# CPSW_PORT register map
Vendor: Texas Instruments
Peripheral module from a debugger description file (folder am437x).
Registers are 32-bit, access per field, no defined reset value unless marked. A register's access mark holds for its fields unless they carry their own. Offsets are as the file gives them; lines under a group give offsets from that group; [hi:lo] are bit positions; {n}, {i} and the like mark numbered series; 'fields as' and 'values as' point back to an identical list; <NAME> marks a mode.

## CPSW_PORT
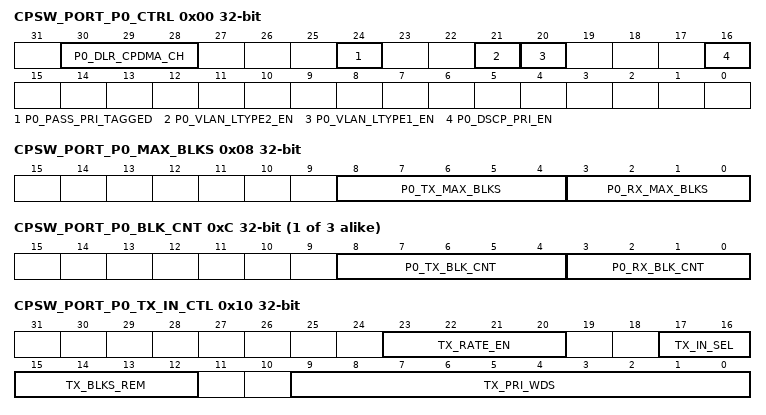
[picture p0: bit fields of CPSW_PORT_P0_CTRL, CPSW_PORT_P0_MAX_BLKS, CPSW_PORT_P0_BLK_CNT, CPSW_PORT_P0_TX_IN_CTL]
0x00 CPSW_PORT_P0_CTRL — CPSW PORT 0 CONTROL REGISTER
  [30:28] P0_DLR_CPDMA_CH rw — Port 0 DLR CPDMA Channel This field indicates the CPDMA channel that DLR packets will be received on.
  [24] P0_PASS_PRI_TAGGED rw — Port 0 Pass Priority Tagged
    1=en_2_0x1 (Priority tagged packets are processed unchanged.); 0=en_1_0x0 (Priority tagged packets have the zero VID replaced with the input port P0_PORT_VLAN[11 to 0])
  [21] P0_VLAN_LTYPE2_EN rw — Port 0 VLAN LTYPE 2 enable
    1=en_2_0x1 (Enabled); 0=en_1_0x0 (Disabled)
  [20] P0_VLAN_LTYPE1_EN rw — Port 0 VLAN LTYPE 1 enable
    1=en_2_0x1 (Enabled); 0=en_1_0x0 (Disabled)
  [16] P0_DSCP_PRI_EN rw — Port 0 DSCP Priority Enable. [[br]]All non-tagged IPV4 packets have their received packet priority determined by mapping the 6 TOS bits through the port DSCP priority mapping registers. [[br]]
    1=en_2_0x1 (DSCP priority enabled); 0=en_1_0x0 (DSCP priority disabled)
0x08 CPSW_PORT_P0_MAX_BLKS — CPSW PORT 0 MAXIMUM FIFO BLOCKS REGISTER
  [8:4] P0_TX_MAX_BLKS rw — Transmit FIFO Maximum Blocks - This value is the maximum number of 1k memory blocks that may be allocated to the FIFO's logical transmit priority queues. [[br]]0x10 is the recommended value of p0_tx_max_blks. [[br]]Port 0 should remain in flow control mode. [[br]]0xe is the minimum value tx max blks. [[br]]
  [3:0] P0_RX_MAX_BLKS rw — Receive FIFO Maximum Blocks - This value is the maximum number of 1k memory blocks that may be allocated to the FIFO's logical receive queue. [[br]]0x4 is the recommended value. [[br]]0x3 is the minimum value rx max blks and 0x6 is the maximum value. [[br]]
{0xC+0x100*i} CPSW_PORT_P{i}_BLK_CNT ro (i=0..2) — CPSW PORT {i} FIFO BLOCK USAGE COUNT (READ ONLY)
  [8:4] P{i}_TX_BLK_CNT — Port {i} Transmit Block Count Usage - This value is the number of blocks allocated to the FIFO logical transmit queues. [[br]]
  [3:0] P{i}_RX_BLK_CNT — Port {i} Receive Block Count Usage - This value is the number of blocks allocated to the FIFO logical receive queues. [[br]]
0x10 CPSW_PORT_P0_TX_IN_CTL — CPSW PORT 0 TRANSMIT FIFO CONTROL
  [23:20] TX_RATE_EN rw — Transmit FIFO Input Rate Enable
  [17:16] TX_IN_SEL rw — Transmit FIFO Input Queue Type Select. [[br]]Note that Dual MAC mode is not compatible with escalation or shaping because dual mac mode forces round robin priority on FIFO egress. [[br]]
    3=en_4_0x3 (Reserved); 2=en_3_0x2 (Rate Limit mode); 1=en_2_0x1 (Dual MAC mode); 0=en_1_0x0 (Normal priority mode)
  [15:12] TX_BLKS_REM rw — Transmit FIFO Input Blocks to subtract in dual mac mode
  [9:0] TX_PRI_WDS rw — Transmit FIFO Words in queue
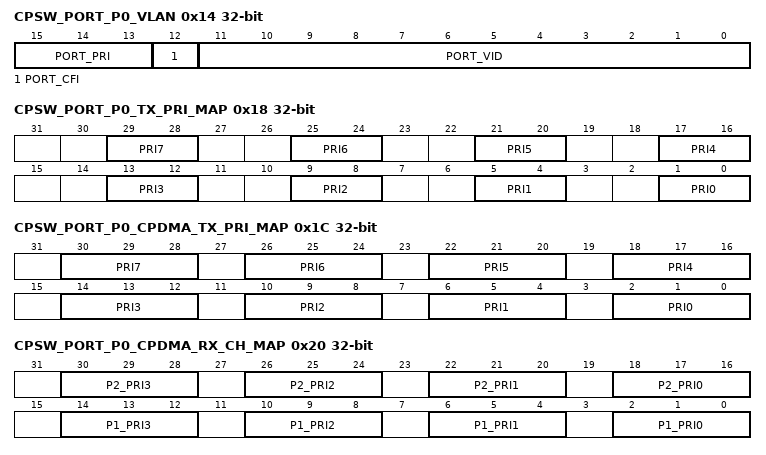
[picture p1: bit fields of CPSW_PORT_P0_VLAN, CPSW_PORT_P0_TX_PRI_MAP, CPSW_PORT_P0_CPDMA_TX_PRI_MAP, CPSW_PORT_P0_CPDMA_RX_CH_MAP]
0x14 CPSW_PORT_P0_VLAN — CPSW PORT 0 VLAN REGISTER
  [15:13] PORT_PRI rw — Port VLAN Priority (7 is highest priority)
  [12] PORT_CFI rw — Port CFI bit
  [11:0] PORT_VID rw — Port VLAN ID
0x18 CPSW_PORT_P0_TX_PRI_MAP — CPSW PORT 0 TX HEADER PRI TO SWITCH PRI MAPPING REGISTER
  [4n+1:4n] PRI{n} rw (n=0..7) — Priority [[br]]{n} - A packet header priority of {0x0+n} is given this switch queue pri.
0x1C CPSW_PORT_P0_CPDMA_TX_PRI_MAP — CPSW CPDMA TX (PORT 0 RX) PKT PRIORITY TO HEADER PRIORITY
  [4n+2:4n] PRI{n} rw (n=0..7) — Priority [[br]]{n} - A packet pri of {0x0+n} is mapped (changed) to this header packet pri.
0x20 CPSW_PORT_P0_CPDMA_RX_CH_MAP — CPSW CPDMA RX (PORT 0 TX) SWITCH PRIORITY TO DMA CHANNEL
  [4n+18:4n+16] P2_PRI{n} rw (n=0..3) — Port 2 Priority {n} packets go to this CPDMA Rx Channel
  [4n+2:4n] P1_PRI{n} rw (n=0..3) — Port 1 Priority {n} packets go to this CPDMA Rx Channel
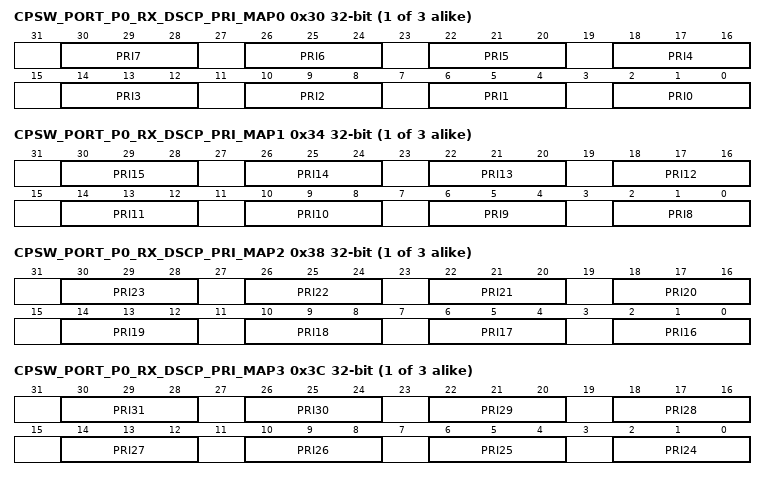
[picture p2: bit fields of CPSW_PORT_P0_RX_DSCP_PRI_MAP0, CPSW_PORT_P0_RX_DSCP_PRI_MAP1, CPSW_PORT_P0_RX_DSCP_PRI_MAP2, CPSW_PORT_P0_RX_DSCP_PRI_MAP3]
{0x30+0x100*i} CPSW_PORT_P{i}_RX_DSCP_PRI_MAP0 (i=0..2) — CPSW PORT {i} RX DSCP PRIORITY TO RX PACKET MAPPING REG 0
  [4n+2:4n] PRI{n} rw (n=0..7) — Priority {n}. [[br]]A packet TOS of 0d{n} is mapped to this received packet priority.
{0x34+0x100*i} CPSW_PORT_P{i}_RX_DSCP_PRI_MAP1 (i=0..2) — CPSW PORT {i} RX DSCP PRIORITY TO RX PACKET MAPPING REG 1
  [4n-30:4n-32] PRI{n} rw (n=8..15) — Priority {n}. [[br]]A packet TOS of 0d{n} is mapped to this received packet priority.
{0x38+0x100*i} CPSW_PORT_P{i}_RX_DSCP_PRI_MAP2 (i=0..2) — CPSW PORT {i} RX DSCP PRIORITY TO RX PACKET MAPPING REG 2
  [4n-62:4n-64] PRI{n} rw (n=16..23) — Priority {n}. [[br]]A packet TOS of 0d{n} is mapped to this received packet priority.
{0x3C+0x100*i} CPSW_PORT_P{i}_RX_DSCP_PRI_MAP3 (i=0..2) — CPSW PORT {i} RX DSCP PRIORITY TO RX PACKET MAPPING REG 3
  [30:28] PRI31 rw — Priority 31. [[br]]A packet TOS of 0d31 is mapped to this received packet priority.
  [26:24] PRI30 rw — Priority 30. [[br]]A packet TOS of 0d30 is mapped to this received packet priority.
  [22:20] PRI29 rw — Priority 29. [[br]]A packet TOS of 0d39 is mapped to this received packet priority.
  [4n-94:4n-96] PRI{n} rw (n=24..28) — Priority {n}. [[br]]A packet TOS of 0d{n} is mapped to this received packet priority.
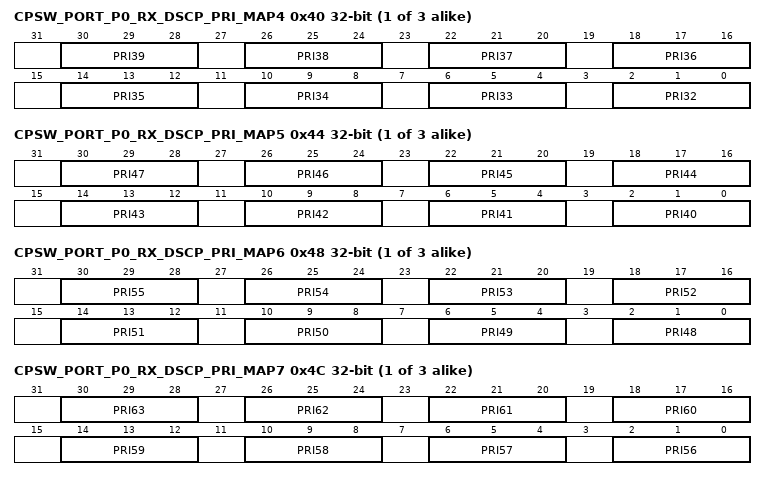
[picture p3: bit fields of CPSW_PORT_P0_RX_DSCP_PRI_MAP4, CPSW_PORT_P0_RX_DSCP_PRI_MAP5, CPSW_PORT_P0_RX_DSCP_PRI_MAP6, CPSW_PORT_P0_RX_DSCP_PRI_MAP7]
{0x40+0x100*i} CPSW_PORT_P{i}_RX_DSCP_PRI_MAP4 (i=0..2) — CPSW PORT {i} RX DSCP PRIORITY TO RX PACKET MAPPING REG 4
  [4n-126:4n-128] PRI{n} rw (n=32..39) — Priority {n}. [[br]]A packet TOS of 0d{n} is mapped to this received packet priority.
{0x44+0x100*i} CPSW_PORT_P{i}_RX_DSCP_PRI_MAP5 (i=0..2) — CPSW PORT {i} RX DSCP PRIORITY TO RX PACKET MAPPING REG 5
  [4n-158:4n-160] PRI{n} rw (n=40..47) — Priority {n}. [[br]]A packet TOS of 0d{n} is mapped to this received packet priority.
{0x48+0x100*i} CPSW_PORT_P{i}_RX_DSCP_PRI_MAP6 (i=0..2) — CPSW PORT {i} RX DSCP PRIORITY TO RX PACKET MAPPING REG 6
  [4n-190:4n-192] PRI{n} rw (n=48..55) — Priority {n}. [[br]]A packet TOS of 0d{n} is mapped to this received packet priority.
{0x4C+0x100*i} CPSW_PORT_P{i}_RX_DSCP_PRI_MAP7 (i=0..2) — CPSW PORT {i} RX DSCP PRIORITY TO RX PACKET MAPPING REG 7
  [4n-222:4n-224] PRI{n} rw (n=56..63) — Priority {n}. [[br]]A packet TOS of 0d{n} is mapped to this received packet priority.
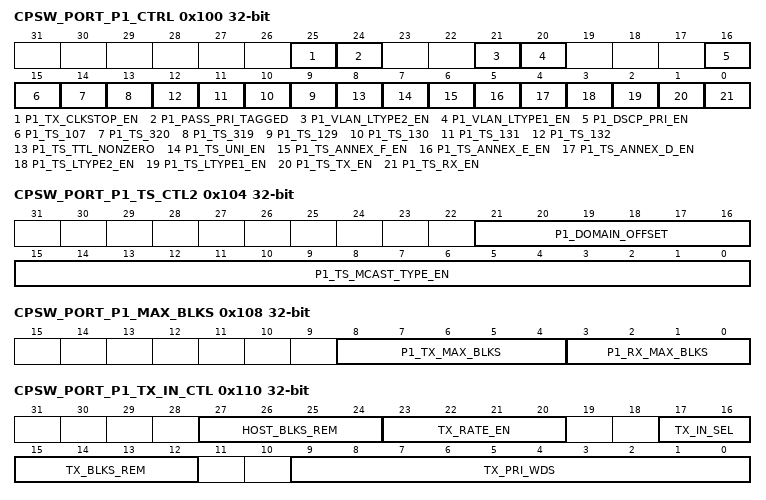
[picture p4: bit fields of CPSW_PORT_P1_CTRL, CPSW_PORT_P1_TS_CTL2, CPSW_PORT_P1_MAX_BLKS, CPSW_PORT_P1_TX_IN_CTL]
0x100 CPSW_PORT_P1_CTRL — CPSW PORT 1 CONTROL REGISTER
  [25] P1_TX_CLKSTOP_EN rw — Port 1 Transmit clockstop enable
    1=en_2_0x1 (RGMII transmit clockstop enabled. The transmit clock will be stopped after the LPI state is entered (and indicated to the CPRGMII) and the P1_Idle2LPI time is counted (counter value reused). The P1_Idle2LPI counter value must be greater than 9 transmit clocks (slowest clock).); 0=en_1_0x0 (RGMII transmit clockstop not enabled)
  [24] P1_PASS_PRI_TAGGED rw — Port 1 Pass Priority Tagged
    1=en_2_0x1 (Priority tagged packets are processed unchanged.); 0=en_1_0x0 (Priority tagged packets have the zero VID replaced with the input port P1_PORT_VLAN[11 to 0])
  [21] P1_VLAN_LTYPE2_EN rw — Port 1 VLAN LTYPE 2 enable
    1=en_2_0x1 (VLAN LTYPE2 enabled on transmit and receive); 0=en_1_0x0 (Disabled)
  [20] P1_VLAN_LTYPE1_EN rw — Port 1 VLAN LTYPE 1 enable
    1=en_2_0x1 (VLAN LTYPE1 enabled on transmit and receive); 0=en_1_0x0 (Disabled)
  [16] P1_DSCP_PRI_EN rw — Port 1 DSCP Priority Enable. [[br]]All non-tagged IPV4 packets have their received packet priority determined by mapping the 6 TOS bits through the port DSCP priority mapping registers.
    values as CPSW_PORT_P0_CTRL.P0_DSCP_PRI_EN
  [15] P1_TS_107 rw — Port 1 Time Sync Destination IP Address 107 enable
    1=en_2_0x1 (Destination IP address (dec) 224.0.0.107 is enabled.); 0=en_1_0x0 (Disabled)
  [14] P1_TS_320 rw — Port 1 Time Sync Destination Port Number 320 enable
    1=en_2_0x1 (Annex D (UDP/IPv4) time sync packet destination port number 320 (decimal) is enabled.); 0=en_1_0x0 (Disabled)
  [13] P1_TS_319 rw — Port 1 Time Sync Destination Port Number 319 enable
    1=en_2_0x1 (Annex D (UDP/IPv4) time sync packet destination port number 319 (decimal) is enabled.); 0=en_1_0x0 (DSCP priority disabled)
  [n-120] P1_TS_{n} rw (n=129..132) — Port 1 Time Sync Destination IP Address {n} enable
    1=en_2_0x1 (Annex D (UDP/IPv4) time sync packet destination IP address number {n} (decimal) is enabled.); 0=en_1_0x0 (DSCP priority disabled)
  [8] P1_TS_TTL_NONZERO rw — Port 1 Time Sync Time To Live Non-zero enable.
    1=en_2_0x1 (TTL may be any value); 0=en_1_0x0 (TTL must be zero)
  [7] P1_TS_UNI_EN rw — Port 1 Time Sync Unicast Enable
    1=en_2_0x1 (Unicast enabled); 0=en_1_0x0 (Unicast disabled)
  [6] P1_TS_ANNEX_F_EN rw — Port 1 Time Sync Annex F enable
    1=en_2_0x1 (Annex F enabled); 0=en_1_0x0 (Annex F disabled)
  [5] P1_TS_ANNEX_E_EN rw — Port 1 Time Sync Annex E enable
    1=en_2_0x1 (Annex E enabled); 0=en_1_0x0 (Annex E disabled)
  [4] P1_TS_ANNEX_D_EN rw — Port 1 Time Sync Annex D enable
    1=en_2_0x1 (Annex D enabled); 0=en_1_0x0 (Annex D disabled)
  [3] P1_TS_LTYPE2_EN rw — Port 1 Time Sync LTYPE 2 enable
    1=en_2_0x1 (Enabled); 0=en_1_0x0 (Disabled)
  [2] P1_TS_LTYPE1_EN rw — Port 1 Time Sync LTYPE 1 enable
    1=en_2_0x1 (Enabled); 0=en_1_0x0 (Disabled)
  [1] P1_TS_TX_EN rw — Port 1 Time Sync Transmit Enable
    1=en_2_0x1 (Enabled); 0=en_1_0x0 (Disabled)
  [0] P1_TS_RX_EN rw — Port 1 Time Sync Receive Enable
    1=en_2_0x1 (Port 1 Receive Time Sync enabled); 0=en_1_0x0 (Port 1 Receive Time Sync disabled)
0x104 CPSW_PORT_P1_TS_CTL2
  [21:16] P1_DOMAIN_OFFSET rw — Domain offset value
  [15:0] P1_TS_MCAST_TYPE_EN rw — Multicast Type Enable
0x108 CPSW_PORT_P1_MAX_BLKS — CPSW PORT 1 MAXIMUM FIFO BLOCKS REGISTER
  [8:4] P1_TX_MAX_BLKS rw — Transmit FIFO Maximum Blocks - This value is the maximum number of 1k memory blocks that may be allocated to the FIFO's logical transmit priority queues. [[br]]0x11 is the recommended value of p1_tx_max_blks unless the port is in fullduplex flow control mode. [[br]]In flow control mode, the p1_rx_max_blks will need to increase in order to accept the required run out in fullduplex mode. [[br]]This value will need to decrease by the amount of increase in p1_rx_max_blks. [[br]]0xe is the minimum value tx max blks. [[br]]
  [3:0] P1_RX_MAX_BLKS rw — Receive FIFO Maximum Blocks - This value is the maximum number of 1k memory blocks that may be allocated to the FIFO's logical receive queue. [[br]]This value must be greater than or equal to 0x3. [[br]]It should be increased In fullduplex flow control mode to 0x5 or 0x6 depending on the required runout space. [[br]]The p1_tx_max_blks value must be decreased by the amount of increase in p1_rx_max_blks. [[br]]0x3 is the minimum value rx max blks and 0x6 is the maximum value. [[br]]
0x110 CPSW_PORT_P1_TX_IN_CTL — CPSW PORT 1 TRANSMIT FIFO CONTROL
  [27:24] HOST_BLKS_REM rw — Transmit FIFO Blocks that must be free before a non rate-limited CPDMA channel can begin sending a packet to the FIFO. [[br]]
  [23:20] TX_RATE_EN rw — Transmit FIFO Input Rate Enable
  [17:16] TX_IN_SEL rw — Transmit FIFO Input Queue Type Select
    3=en_4_0x3 (Reserved); 2=en_3_0x2 (Rate Limit mode); 1=en_2_0x1 (Reserved); 0=en_1_0x0 (Normal priority mode)
  [15:12] TX_BLKS_REM rw — Transmit FIFO Input Blocks to subtract in dual mac mode and blocks to subtract on non rate-limited traffic in rate-limit mode. [[br]]
  [9:0] TX_PRI_WDS rw — Transmit FIFO Words in queue
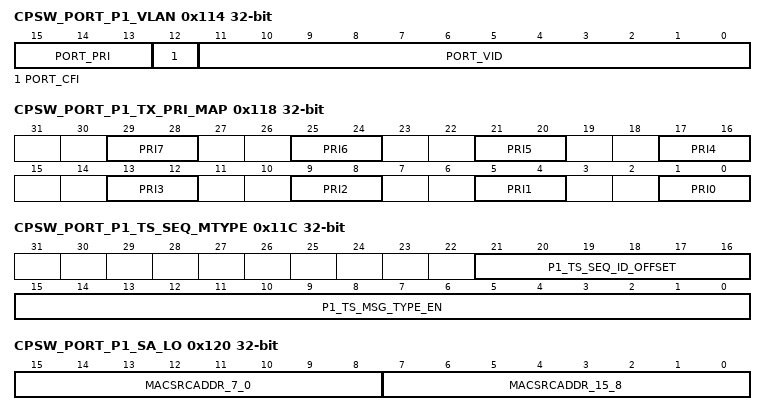
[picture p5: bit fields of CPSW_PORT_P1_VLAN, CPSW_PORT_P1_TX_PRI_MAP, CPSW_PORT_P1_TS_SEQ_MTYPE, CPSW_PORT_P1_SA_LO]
0x114 CPSW_PORT_P1_VLAN — CPSW PORT 1 VLAN REGISTER
  fields as CPSW_PORT_P0_VLAN
0x118 CPSW_PORT_P1_TX_PRI_MAP — CPSW PORT 1 TX HEADER PRIORITY TO SWITCH PRI MAPPING REGISTER
  fields as CPSW_PORT_P0_TX_PRI_MAP
0x11C CPSW_PORT_P1_TS_SEQ_MTYPE — CPSW PORT 1 TIME SYNC SEQUENCE ID OFFSET AND MSG TYPE.
  [21:16] P1_TS_SEQ_ID_OFFSET rw — Port 1 Time Sync Sequence ID Offset This is the number of octets that the sequence ID is offset in the tx and rx time sync message header. [[br]]The minimum value is 6. [[br]]
  [15:0] P1_TS_MSG_TYPE_EN rw — Port 1 Time Sync Message Type Enable - Each bit in this field enables the corresponding message type in receive and transmit time sync messages (Bit 0 enables message type 0 etc.). [[br]]
0x120 CPSW_PORT_P1_SA_LO — CPSW CPGMAC_SL1 SOURCE ADDRESS LOW REGISTER
  [15:8] MACSRCADDR_7_0 rw — Source Address Lower 8 bits (byte 0)
  [7:0] MACSRCADDR_15_8 rw — Source Address bits 15 to 8 (byte 1)
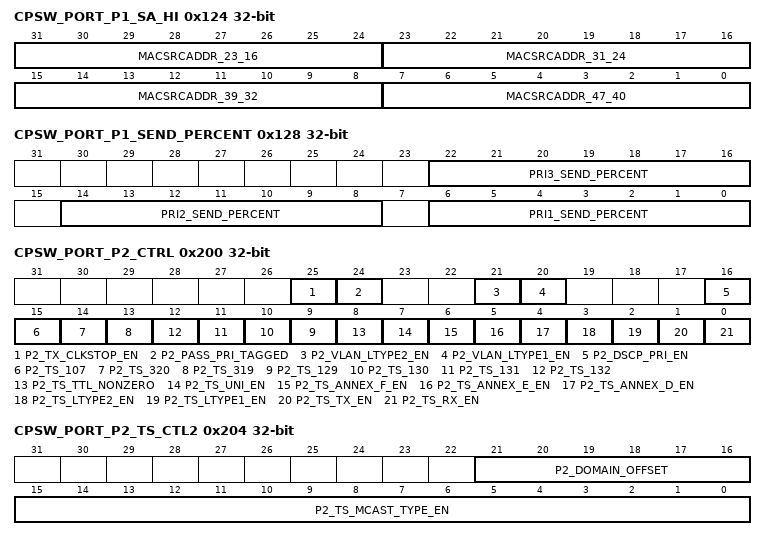
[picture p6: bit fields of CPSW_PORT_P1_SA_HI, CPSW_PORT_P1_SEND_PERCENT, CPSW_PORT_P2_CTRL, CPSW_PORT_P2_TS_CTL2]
0x124 CPSW_PORT_P1_SA_HI rw — CPSW CPGMAC_SL1 SOURCE ADDRESS HIGH REGISTER
  [31:24] MACSRCADDR_23_16 — Source Address bits 23 to 16 (byte 2)
  [23:16] MACSRCADDR_31_24 — Source Address bits 31 to 24 (byte 3)
  [15:8] MACSRCADDR_39_32 — Source Address bits 39 to 32 (byte 4)
  [7:0] MACSRCADDR_47_40 — Source Address bits 47 to 40 (byte 5)
0x128 CPSW_PORT_P1_SEND_PERCENT — CPSW PORT 1 TRANSMIT QUEUE SEND PERCENTAGES
  [22:16] PRI3_SEND_PERCENT rw — Priority 3 Transmit Percentage - This percentage value is sent from FIFO priority 3 (maximum) when the p1_pri3_shape_en is set (queue shaping enabled). [[br]]This is the percentage of the wire that packets from priority 3 receive (which includes interpacket gap and preamble bytes). [[br]]If shaping is enabled on this queue then this value must be between zero and 0d100 (not inclusive). [[br]]
  [14:8] PRI2_SEND_PERCENT rw — Priority 2 Transmit Percentage - This percentage value is sent from FIFO priority 2 (maximum) when the p1_pri2_shape_en is set (queue shaping enabled). [[br]]This is the percentage of the wire that packets from priority 2 receive (which includes interpacket gap and preamble bytes). [[br]]If shaping is enabled on this queue then this value must be between zero and 0d100 (not inclusive). [[br]]
  [6:0] PRI1_SEND_PERCENT rw — Priority 1 Transmit Percentage - This percentage value is sent from FIFO priority 1 (maximum) when the p1_pri1_shape_en is set (queue shaping enabled). [[br]]This is the percentage of the wire that packets from priority 1 receive (which includes interpacket gap and preamble bytes). [[br]]If shaping is enabled on this queue then this value must be between zero and 0d100 (not inclusive). [[br]]
0x200 CPSW_PORT_P2_CTRL access not given — CPSW_3GF PORT 2 CONTROL REGISTER
  [25] P2_TX_CLKSTOP_EN rw — Port 2 Transmit clockstop enable
    1=en_2_0x1 (RGMII transmit clockstop enabled. The transmit clock will be stopped after the LPI state is entered (and indicated to the CPRGMII) and the P2_Idle2LPI time is counted (counter value reused). The P2_Idle2LPI counter value must be greater than 9 transmit clocks (slowest clock).); 0=en_1_0x0 (RGMII transmit clockstop not enabled)
  [24] P2_PASS_PRI_TAGGED rw — Port 2 Pass Priority Tagged
    1=en_2_0x1 (Priority tagged packets are processed unchanged.); 0=en_1_0x0 (Priority tagged packets have the zero VID replaced with the input port P2_PORT_VLAN[11 to 0])
  [21] P2_VLAN_LTYPE2_EN rw — Port 2 VLAN LTYPE 2 enable
    values as CPSW_PORT_P1_CTRL.P1_VLAN_LTYPE2_EN
  [20] P2_VLAN_LTYPE1_EN rw — Port 2 VLAN LTYPE 1 enable
    values as CPSW_PORT_P1_CTRL.P1_VLAN_LTYPE1_EN
  [16] P2_DSCP_PRI_EN rw — Port 0 DSCP Priority Enable. [[br]]All non-tagged IPV4 packets have their received packet priority determined by mapping the 6 TOS bits through the port DSCP priority mapping registers. [[br]]
    values as CPSW_PORT_P0_CTRL.P0_DSCP_PRI_EN
  [15] P2_TS_107 — Port 2 Time Sync Destination IP Address 107 enable
    values as CPSW_PORT_P1_CTRL.P1_TS_107
  [14] P2_TS_320 rw — Port 2 Time Sync Destination Port Number 320 enable
    values as CPSW_PORT_P1_CTRL.P1_TS_320
  [13] P2_TS_319 rw — Port 2 Time Sync Destination Port Number 319 enable
    values as CPSW_PORT_P1_CTRL.P1_TS_319
  [n-120] P2_TS_{n} rw (n=129..132) — Port 2 Time Sync Destination IP Address {n} enable
    values as CPSW_PORT_P1_CTRL.P1_TS_129
  [8] P2_TS_TTL_NONZERO rw — Port 2 Time Sync Time To Live Non-zero enable. [[br]]
    values as CPSW_PORT_P1_CTRL.P1_TS_TTL_NONZERO
  [7] P2_TS_UNI_EN rw — Port 2 Time Sync Unicast Enable
    1=en_2_0x1 (Unicast enabled); 0=en_1_0x0 (Unicast disabled)
  [6] P2_TS_ANNEX_F_EN rw — Port 2 Time Sync Annex F enable
    1=en_2_0x1 (Annex F enabled); 0=en_1_0x0 (Annex F disabled)
  [5] P2_TS_ANNEX_E_EN rw — Port 2 Time Sync Annex E enable
    1=en_2_0x1 (Annex E enabled); 0=en_1_0x0 (Annex E disabled)
  [4] P2_TS_ANNEX_D_EN rw — Port 2 Time Sync Annex D enable
    1=en_2_0x1 (Annex D enabled); 0=en_1_0x0 (Annex D disabled)
  [3] P2_TS_LTYPE2_EN ro — Port 2 Time Sync LTYPE 2 enable
    1=en_2_0x1 (Enabled); 0=en_1_0x0 (Disabled)
  [2] P2_TS_LTYPE1_EN rw — Port 2 Time Sync LTYPE 1 enable
    1=en_2_0x1 (Enabled); 0=en_1_0x0 (Disabled)
  [1] P2_TS_TX_EN rw — Port 2 Time Sync Transmit Enable
    1=en_2_0x1 (Enabled); 0=en_1_0x0 (Disabled)
  [0] P2_TS_RX_EN rw — Port 2 Time Sync Receive Enable
    values as CPSW_PORT_P1_CTRL.P1_TS_RX_EN
0x204 CPSW_PORT_P2_TS_CTL2
  [21:16] P2_DOMAIN_OFFSET rw — Domain offset value
  [15:0] P2_TS_MCAST_TYPE_EN rw — Multicast Type Enable
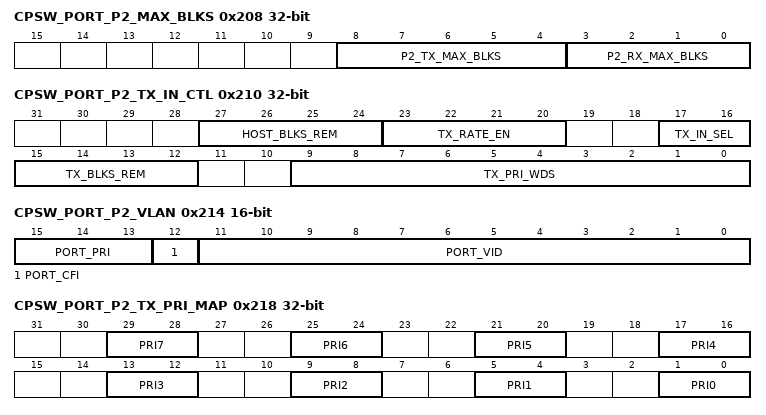
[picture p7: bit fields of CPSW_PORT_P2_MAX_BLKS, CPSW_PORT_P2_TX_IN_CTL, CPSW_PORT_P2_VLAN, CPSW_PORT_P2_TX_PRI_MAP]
0x208 CPSW_PORT_P2_MAX_BLKS — CPSW PORT 2 MAXIMUM FIFO BLOCKS REGISTER
  [8:4] P2_TX_MAX_BLKS rw — Transmit FIFO Maximum Blocks - This value is the maximum number of 1k memory blocks that may be allocated to the FIFO's logical transmit priority queues. [[br]]0x11 is the recommended value of p2_tx_max_blks unless the port is in fullduplex flow control mode. [[br]]In flow control mode, the p2_rx_max_blks will need to increase in order to accept the required run out in fullduplex mode. [[br]]This value will need to decrease by the amount of increase in p2_rx_max_blks. [[br]]0xe is the minimum value tx max blks. [[br]]
  [3:0] P2_RX_MAX_BLKS rw — Receive FIFO Maximum Blocks - This value is the maximum number of 1k memory blocks that may be allocated to the FIFO's logical receive queue. [[br]]This value must be greater than or equal to 0x3. [[br]]It should be increased In fullduplex flow control mode to 0x5 or 0x6 depending on the required runout space. [[br]]The p2_tx_max_blks value must be decreased by the amount of increase in p2_rx_max_blks. [[br]]0x3 is the minimum value rx max blks and 0x6 is the maximum value. [[br]]
0x210 CPSW_PORT_P2_TX_IN_CTL — CPSW PORT 2 TRANSMIT FIFO CONTROL
  fields as CPSW_PORT_P1_TX_IN_CTL
0x214 CPSW_PORT_P2_VLAN 16-bit rw — CPSW PORT 2 VLAN REGISTER
  [15:13] PORT_PRI — Port VLAN Priority (7 is highest priority)
  [12] PORT_CFI — Port CFI bit
  [11:0] PORT_VID — Port VLAN ID
0x218 CPSW_PORT_P2_TX_PRI_MAP — CPSW PORT 2 TX HEADER PRIORITY TO SWITCH PRI MAPPING REGISTER
  fields as CPSW_PORT_P0_TX_PRI_MAP
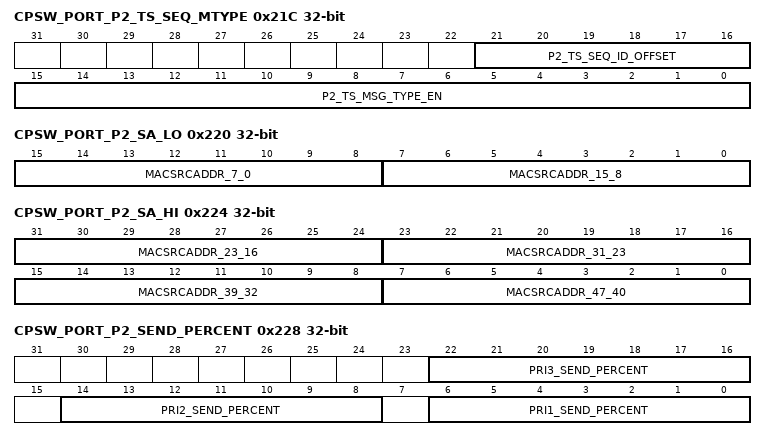
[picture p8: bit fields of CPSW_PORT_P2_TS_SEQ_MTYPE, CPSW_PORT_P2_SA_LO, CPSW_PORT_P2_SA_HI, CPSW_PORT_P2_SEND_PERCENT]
0x21C CPSW_PORT_P2_TS_SEQ_MTYPE — CPSW_3GF PORT 2 TIME SYNC SEQUENCE ID OFFSET AND MSG TYPE.
  [21:16] P2_TS_SEQ_ID_OFFSET rw — Port 2 Time Sync Sequence ID Offset This is the number of octets that the sequence ID is offset in the tx and rx time sync message header. [[br]]The minimum value is 6. [[br]]
  [15:0] P2_TS_MSG_TYPE_EN rw — Port 2 Time Sync Message Type Enable - Each bit in this field enables the corresponding message type in receive and transmit time sync messages (Bit 0 enables message type 0 etc.). [[br]]
0x220 CPSW_PORT_P2_SA_LO — CPSW CPGMAC_SL2 SOURCE ADDRESS LOW REGISTER
  fields as CPSW_PORT_P1_SA_LO
0x224 CPSW_PORT_P2_SA_HI rw — CPSW CPGMAC_SL2 SOURCE ADDRESS HIGH REGISTER
  [31:24] MACSRCADDR_23_16 — Source Address bits 23 to 16 (byte 2)
  [23:16] MACSRCADDR_31_23 — Source Address bits 31 to 23 (byte 3)
  [15:8] MACSRCADDR_39_32 — Source Address bits 39 to 32 (byte 4)
  [7:0] MACSRCADDR_47_40 — Source Address bits 47 to 40 (byte 5)
0x228 CPSW_PORT_P2_SEND_PERCENT — CPSW PORT 2 TRANSMIT QUEUE SEND PERCENTAGES
  fields as CPSW_PORT_P1_SEND_PERCENT
